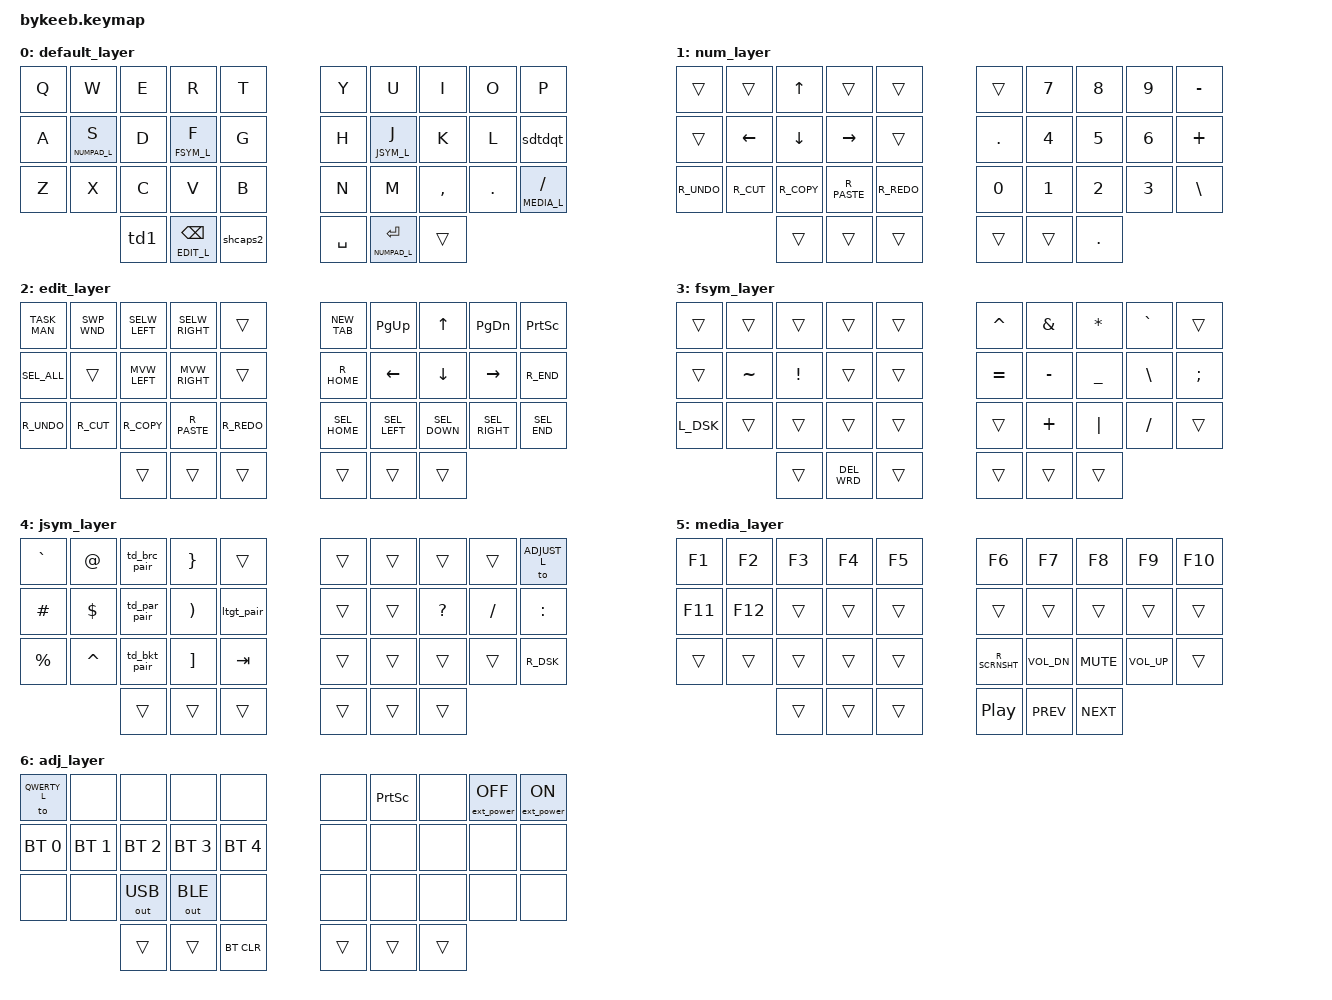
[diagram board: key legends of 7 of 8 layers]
/*
 * Copyright (c) 2020 The ZMK Contributors
 *
 * SPDX-License-Identifier: MIT
 */

 #include <behaviors.dtsi>
 #include <dt-bindings/zmk/keys.h>
 #include <dt-bindings/zmk/bt.h>
 #include <dt-bindings/zmk/ext_power.h>
 #include <dt-bindings/zmk/outputs.h>
 #include <dt-bindings/zmk/mouse.h>
 #include <behaviors/mouse_keys.dtsi>
 
#define QWERTY_L 0
#define NUMPAD_L 1
#define EDIT_L 2
#define FSYM_L 3
#define JSYM_L 4
#define MEDIA_L 5
#define ADJUST_L 6
#define LAYERLEADER_L 7

#define R_UNDO      LG(Z)
#define R_REDO      LG(Y)
#define R_CUT       LG(X)
#define R_COPY      LG(C)
#define R_PASTE     LG(V)
#define R_SAVE      RG(S)
#define NEW_TAB     LG(T)
#define SWP_WND     LG(GRAVE)
#define R_HOME      LG(LEFT)
#define R_END       LG(RIGHT)
#define ZOOM_IN     LG(EQUAL)
#define ZOOM_OUT    LG(MINUS)
#define L_DSK       LC(LEFT)
#define R_DSK       LC(RIGHT)
#define DEL_WRD     LA(BSPC)
#define MVW_LEFT    LA(LEFT) 
#define MVW_RIGHT   LA(RIGHT)
#define SELW_LEFT   LA(RS(LEFT))
#define SELW_RIGHT  LA(RS(RIGHT))
#define TASK_MAN    LG(LA(ESCAPE))
#define SEL_HOME    RS(LG(LEFT))
#define SEL_END     RS(LG(RIGHT))
#define SEL_LEFT    RS(LEFT)
#define SEL_DOWN    RS(DOWN)
#define SEL_RIGHT   RS(RIGHT)
#define R_SCRNSHT   RS(RG(N4))
#define SFTCMD      RS(RGUI)
#define SEL_ALL     RG(A)
#define SWP_APP     RG(TAB)

&sk {
    release-after-ms = <900>;
    quick-release;
};
&lt { quick_tap_ms = <200>; };

/ {
    combos {
        compatible = "zmk,combos";

    // shortcut
    #define COMBO(NAME, BINDINGS, KEYPOS, TIMEOUT) \
        combo_##NAME { \
            timeout-ms = <TIMEOUT>; \
            bindings = <BINDINGS>; \
            layers = <0>; \
            key-positions = <KEYPOS>; \
    };

    #define COMBO2(NAME, BINDINGS, KEYPOS, TIMEOUT) \
        combo_##NAME { \
            timeout-ms = <TIMEOUT>; \
            bindings = <BINDINGS>; \
            layers = <0>; \
            require-prior-idle-ms = 20; \
            key-positions = <KEYPOS>; \
    };
       

        /*                KEY POSITIONS

          ╭────────────────────╮╭────────────────────╮
          │ 0   1   2   3   4  ││  5   6   7   8   9 │
          │ 10  11  12  13  14 ││ 15  16  17  18  19 │
          │ 20  21  22  23  24 ││ 25  26  27  28  29 │
          ╰───────╮ 30  31  32 ││ 33  34  35 ╭───────╯
                  ╰────────────╯╰────────────╯        */

        COMBO(tab,     &kp TAB,    14 24,    30)
        COMBO(escape,  &kp ESCAPE, 4 5,    30)
        COMBO(scl,     &kp SEMI,    19 29,    30)
        COMBO(dskr,    &kp R_DSK,  28 29,   30)
        COMBO(dskl,    &kp L_DSK,  20 21,   30)
        //COMBO(equal, &kp EQUAL, 12 23, 100)
        COMBO(enter, &kp ENTER, 12 17, 30)
        COMBO(reset_l, &bootloader, 0 1 2 3, 100)
        COMBO(reset_right, &bootloader, 6 7 8 9, 100)
        // dude cross-hand combos are awesome! 
        // put in cross-hand homerow mod sticky combos???? 
        COMBO(rcmd, &sk RGUI, 6 16, 30)
        COMBO(ropt, &sk RALT, 7 17, 30)
        COMBO(rctrl, &sk RCTRL, 8 18, 30)
        //COMBO(rcmdctrl, &sk RGUI &sk RCTRL, 13 22, 30)
        COMBO(rsftcmd,  &sk RS(RGUI),  5 15, 30)
        COMBO(lcmd, &sk LGUI, 3 13, 30)
        COMBO(lopt, &sk LALT, 2 12, 30)
        COMBO(lctrl, &sk LCTRL, 1 11, 30)
        //COMBO(lcmdctrl, &sk RGUI &sk RCTRL, 13 22, 30)
        COMBO(lsftcmd,  &sk LS(LGUI),  4 14, 30)
    };

    macros {
        ZMK_MACRO(pair_par, wait-ms = <30>; tap-ms = <40>; bindings = <&kp LPAR &kp RPAR>;)
        ZMK_MACRO(pair_par2, wait-ms = <30>; tap-ms = <40>; bindings = <&kp LPAR &kp RPAR>, <&kp LEFT>;)
        ZMK_MACRO(pair_brc, wait-ms = <30>; tap-ms = <40>; bindings = <&kp LBRC &kp RBRC>;)
        ZMK_MACRO(pair_brc2, wait-ms = <30>; tap-ms = <40>; bindings = <&kp LBRC &kp RBRC>, <&kp LEFT>;)
        ZMK_MACRO(pair_bkt, wait-ms = <30>; tap-ms = <40>; bindings = <&kp LBKT &kp RBKT>;)
        ZMK_MACRO(pair_bkt2, wait-ms = <30>; tap-ms = <40>; bindings = <&kp LBKT &kp RBKT>, <&kp LEFT>;)
        ZMK_MACRO(ltgt_pair, wait-ms = <30>; tap-ms = <40>; bindings = <&kp LT &kp GT>, <&kp LEFT>;)
        ZMK_MACRO(up3, wait-ms = <30>; tap-ms = <40>; bindings = <&kp UP &kp UP &kp UP>;)
        ZMK_MACRO(down3, wait-ms = <30>; tap-ms = <40>; bindings = <&kp DOWN &kp DOWN &kp DOWN>;)
        ZMK_MACRO(squotes, wait-ms = <30>; tap-ms = <40>; bindings = <&kp SQT &kp SQT &kp LEFT>;)
        ZMK_MACRO(dquotes, wait-ms = <30>; tap-ms = <40>; bindings = <&kp DQT &kp DQT &kp LEFT>;)
        };

    behaviors {
        #define TAPDANCE(name,...) \
            name: name { \
            compatible = "zmk,behavior-tap-dance"; \
            #binding-cells = <0>; \
            __VA_ARGS__ \
        };
        ht: hold-tap {
                compatible = "zmk,behavior-hold-tap";
                label = "HOLD_TAP";
                #binding-cells = <2>;
                flavor = "hold-preferred";
                tapping-term-ms = <400>;
                quick-tap-ms = <200>;
                bindings = <&kp>, <&kp>;
        };
        TAPDANCE(bkfwd, tapping-term-ms = <300>; bindings = <&kp LG(LEFT)>, <&kp LG(RIGHT)>;)
        TAPDANCE(td1, tapping-term-ms = <300>; bindings = <&sk RGUI>, <&sk RALT>, <&sk RCTRL>;)
        TAPDANCE(td2, tapping-term-ms = <300>; bindings = <&sk RALT>, <&sk RGUI>, <&sk RCTRL>;)
        TAPDANCE(shcaps, tapping-term-ms = <300>; bindings = <&sk LSHIFT>, <&caps_word>;)
        TAPDANCE(shcaps2, tapping-term-ms = <300>; bindings = <&sk LSHIFT>, <&caps_word>, <&kp CAPSLOCK>;)
        TAPDANCE(td_par_pair, tapping-term-ms = <300>; bindings = <&kp LPAR>, <&pair_par>, <&pair_par2>;)
        TAPDANCE(td_brc_pair, tapping-term-ms = <300>; bindings = <&kp LBRC>, <&pair_brc>, <&pair_brc2>;)
        TAPDANCE(td_bkt_pair, tapping-term-ms = <300>; bindings = <&kp LBKT>, <&pair_bkt>, <&pair_bkt2>;)
        TAPDANCE(squotespair, tapping-term-ms = <300>; bindings = <&kp SQT>, <&squotes>;)
        TAPDANCE(dquotespair, tapping-term-ms = <300>; bindings = <&kp DQT>, <&dquotes>;)
        sdtdqt: sqt_dqt {
            compatible = "zmk,behavior-mod-morph";
            label = "sqtdqt";
            #binding-cells = <0>;
            bindings = <&squotespair>, <&dquotespair>;
            mods = <(MOD_LSFT|MOD_RSFT)>;
        };
    };
 
     keymap {
         compatible = "zmk,keymap";
                // QWERTY
        default_layer { 
                bindings = <    // figure out how to do a holdable or tapable layer switch for the numpad  
                &kp  Q    &kp  W         &kp  E     &kp  R           &kp  T          &kp  Y    &kp  U        &kp  I        &kp  O     &kp  P
                &kp  A    &lt NUMPAD_L S &kp  D     &lt FSYM_L  F    &kp  G          &kp  H    &lt JSYM_L J  &kp  K        &kp  L     &sdtdqt
                &kp  Z    &kp  X         &kp  C     &kp  V           &kp  B          &kp  N    &kp  M        &kp  COMMA    &kp  DOT   &lt MEDIA_L SLASH
                                         &td1       &lt EDIT_L BSPC  &shcaps2        &kp SPACE  &lt NUMPAD_L ENTER   &trans   
                >;
         };

        num_layer {
                bindings = <
                &trans     &trans    &kp UP     &trans      &trans                     &trans   &kp  N7   &kp  N8   &kp  N9     &kp  MINUS
                &trans     &kp LEFT  &kp DOWN   &kp RIGHT   &trans                     &kp DOT  &kp  N4   &kp  N5   &kp  N6     &kp  PLUS    
                &kp R_UNDO &kp R_CUT &kp R_COPY &kp R_PASTE &kp R_REDO                 &kp N0   &kp  N1   &kp  N2   &kp  N3     &kp  BSLH     
                                                    &trans &trans &trans           &trans  &trans  &kp DOT  
                >;
};

        edit_layer {
                bindings = <
                &kp TASK_MAN &kp SWP_WND    &kp SELW_LEFT &kp SELW_RIGHT &trans                           &kp NEW_TAB &kp PG_UP &kp UP &kp PG_DN &kp PSCRN 
                &kp SEL_ALL  &trans         &kp MVW_LEFT  &kp MVW_RIGHT  &trans                           &kp  R_HOME  &kp LEFT &kp DOWN &kp RIGHT &kp R_END 
                &kp R_UNDO   &kp R_CUT &kp R_COPY    &kp R_PASTE    &kp R_REDO                            &kp SEL_HOME &kp SEL_LEFT &kp SEL_DOWN &kp SEL_RIGHT &kp SEL_END 
                &trans  &trans  &trans                                                   &trans  &trans  &trans  
                >;
        };

        fsym_layer {
                bindings = <
                &trans &trans &trans &trans &trans                                     &kp CARET &kp AMPS &kp ASTRK &kp GRAVE &trans  
                &trans  &kp TILDE &kp EXCL &trans &trans                                     &kp EQUAL &kp MINUS &kp UNDER &kp BSLH &kp SEMI
                &kp L_DSK  &trans  &trans  &trans  &trans                                   &trans &kp PLUS &kp PIPE &kp SLASH &trans 
                &trans &kp DEL_WRD &trans                    &trans &trans &trans   
                >;
        };

        jsym_layer {
                bindings = <
                &kp GRAVE &kp AT    &td_brc_pair &kp RBRC  &trans                   &trans &trans &trans &trans &to ADJUST_L 
                &kp HASH  &kp DLLR  &td_par_pair &kp RPAR  &ltgt_pair               &trans &trans &kp QMARK &kp SLASH &kp COLON 
                &kp PRCNT &kp CARET &td_bkt_pair &kp RBKT  &kp TAB                  &trans &trans &trans &trans &kp R_DSK 
                &trans    &trans   &trans                                           &trans &trans &trans 
                >;
        };      

        media_layer {
                bindings = <
                &kp F1 &kp F2 &kp F3 &kp F4  &kp F5       &kp F6  &kp F7 &kp F8 &kp F9 &kp F10                                                
                &kp F11 &kp F12 &trans &trans &trans      &trans &trans &trans &trans &trans
                &trans &trans &trans  &trans  &trans      &kp R_SCRNSHT &kp C_VOL_DN &kp K_MUTE &kp C_VOL_UP  &trans  
                &trans  &trans  &trans                    &kp C_PP  &kp C_PREV  &kp C_NEXT  
                >;
        };

        adj_layer {
                bindings = <
                &to  QWERTY_L &none &none &none  &none                            &none      &kp PRINTSCREEN    &none         &ext_power EP_OFF  &ext_power EP_ON 
                &bt  BT_SEL 0 &bt  BT_SEL 1 &bt  BT_SEL 2 &bt  BT_SEL 3 &bt  BT_SEL 4             &none      &none              &none         &none              &none            
                &none        &none         &out OUT_USB  &out OUT_BLE  &none                      &none      &none              &none         &none              &none            
                &trans       &trans        &bt BT_CLR                 &trans   &trans     &trans                     
                >;
        };

        layerleader_layer {
                bindings = <
                &none &none         &none   &none  &none                      &none  &none      &none       &none  &to NUMPAD_L
                &none &to NUMPAD_L   &none  &to FSYM_L &none                  &none  &to JSYM_L &to FSYM_L  &none  &to EDIT_L   
                &none &none         &none   &none  &none                      &none      &none       &none  &to MEDIA_L  
                             &trans &to EDIT_L &to QWERTY_L       &to QWERTY_L  &to NUMPAD_L  &trans    
                >;

        };
     };
 };
 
